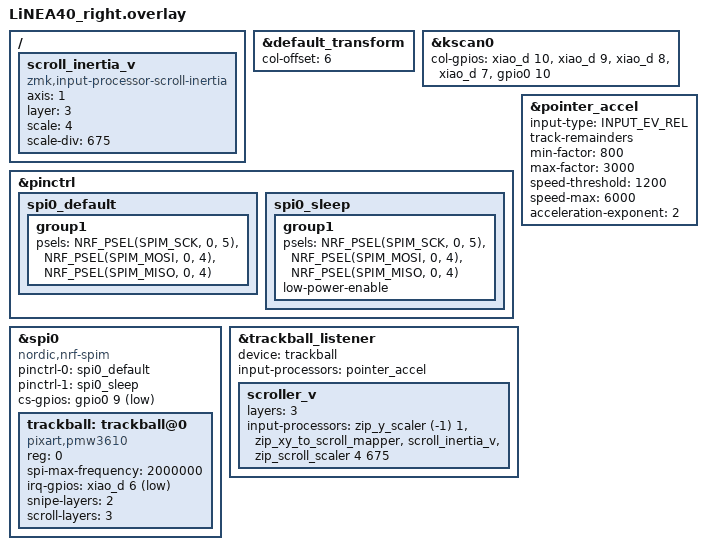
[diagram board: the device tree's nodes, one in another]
#include "LiNEA40.dtsi"
#include <input/processors.dtsi>
#include <behaviors/input_gestures_accel.dtsi>
#include <dt-bindings/zmk/modifiers.h>

&default_transform {
    col-offset = <6>;
};

&kscan0 {
    col-gpios
        = <&xiao_d 10 GPIO_ACTIVE_HIGH> //col0-D10
        , <&xiao_d 9 GPIO_ACTIVE_HIGH>  //col1-D9
        , <&xiao_d 8 GPIO_ACTIVE_HIGH>  //col2-D8
        , <&xiao_d 7 GPIO_ACTIVE_HIGH>  //col3-D7
        , <&gpio0 10 GPIO_ACTIVE_HIGH>  //col4-NFC2
        ;
};

/ {
    scroll_inertia_v: scroll_inertia_v {
        compatible = "zmk,input-processor-scroll-inertia";
        #input-processor-cells = <0>;

        /* axis: 0 = 両軸（自由2D）,
                  1 = Y軸のみ（縦スクロール）,
                  2 = X軸のみ（横スクロール） */
        axis      = <1>;
        layer     = <3>;          /* 縦スクロール用のレイヤー番号 */

        /* 後段の zip_scroll_scaler の引数と合わせる */
        scale     = <4>;
        scale-div = <675>;

    };
};



/*
/ {
    trackball_listener {
        compatible = "zmk,input-listener";
        device = <&trackball>;

    };
};
*/


&pinctrl {
    spi0_default: spi0_default {
        group1 {
            psels = <NRF_PSEL(SPIM_SCK, 0, 5)>   // SCLK-D5
                  , <NRF_PSEL(SPIM_MOSI, 0, 4)>  // SDIO-D4
                  , <NRF_PSEL(SPIM_MISO, 0, 4)>  // SDIO-D4
                  ;
        };
    };

    spi0_sleep: spi0_sleep {
        group1 {
            psels = <NRF_PSEL(SPIM_SCK, 0, 5)>   // SCLK-D5
                  , <NRF_PSEL(SPIM_MOSI, 0, 4)>  // SDIO-D4
                  , <NRF_PSEL(SPIM_MISO, 0, 4)>  // SDIO-D4
                  ;
            low-power-enable;
        };
    };
};

&spi0 {
    status = "okay";
    compatible = "nordic,nrf-spim";
    pinctrl-0 = <&spi0_default>;
    pinctrl-1 = <&spi0_sleep>;
    pinctrl-names = "default", "sleep";
    cs-gpios = <&gpio0 9 GPIO_ACTIVE_LOW>; //NCS-NFC1

    trackball: trackball@0 {
        status = "okay";
        compatible = "pixart,pmw3610";
        reg = <0>;
        spi-max-frequency = <2000000>;
        irq-gpios = <&xiao_d 6 (GPIO_ACTIVE_LOW | GPIO_PULL_UP)>; //MOT-D6
        //automouse-layer = <1>; 20261031 無効化
        snipe-layers = <2>;
        scroll-layers = <3>;
        //scroll-layers = <4 5 6>;
    };
};

&pointer_accel {
    input-type = <INPUT_EV_REL>;  // For relative input devices
    track-remainders;             // Accumulate fractional movements
    min-factor = <800>;          // 0.8x at very slow speeds
    max-factor = <3000>;         // 3.0x at fast speeds
    speed-threshold = <1200>;     // 1200 counts/sec for 1x
    speed-max = <6000>;          // 6000 counts/sec for max accel
    acceleration-exponent = <2>;  // Quadratic acceleration curve
};

&trackball_listener {
    status = "okay";
    device = <&trackball>;
    input-processors = <&pointer_accel>;

    scroller_v {
    layers = <3>;
    input-processors = <
        &zip_y_scaler (-1) 1
        &zip_xy_to_scroll_mapper
        &scroll_inertia_v
        &zip_scroll_scaler 4 675
    >;
    };
};



